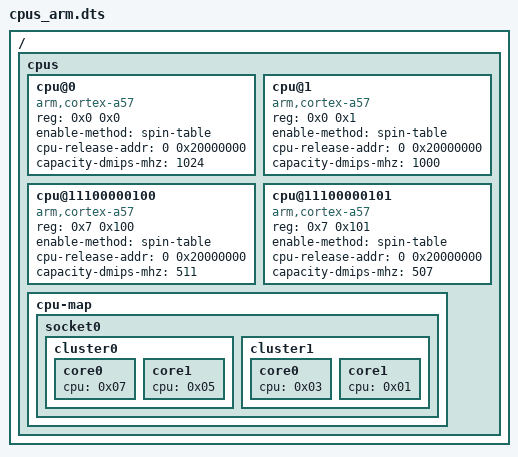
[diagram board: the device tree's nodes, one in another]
// Copyright 2023 The Fuchsia Authors. All rights reserved.
// Use of this source code is governed by a BSD-style license that can be
// found in the LICENSE file.

/dts-v1/;

/ {
    cpus {
        #size-cells = <0>;
        #address-cells = <2>;

        cpu@0 {
            device_type = "cpu";
            compatible = "arm,cortex-a57";
            reg = <0x0 0x0>;
            enable-method = "spin-table";
            cpu-release-addr = <0 0x20000000>;
            phandle = <0x01>;
            capacity-dmips-mhz = <1024>;
        };

        cpu@1 {
            device_type = "cpu";
            compatible = "arm,cortex-a57";
            reg = <0x0 0x1>;
            enable-method = "spin-table";
            cpu-release-addr = <0 0x20000000>;
            phandle = <0x03>;
            capacity-dmips-mhz = <1000>;
        };

        cpu@11100000100 {
            device_type = "cpu";
            compatible = "arm,cortex-a57";
            reg = <0x7 0x100>;
            enable-method = "spin-table";
            cpu-release-addr = <0 0x20000000>;
            phandle = <0x05>;
            capacity-dmips-mhz = <511>;
        };

        cpu@11100000101 {
            device_type = "cpu";
            compatible = "arm,cortex-a57";
            reg = <0x7 0x101>;
            enable-method = "spin-table";
            cpu-release-addr = <0 0x20000000>;
            phandle = <0x07>;
            capacity-dmips-mhz = <507>;
        };

        cpu-map {
            socket0 {
                cluster0 {
                    core0 {
                        cpu = <0x07>;
                    };

                    core1 {
                        cpu = <0x05>;
                    };
                };
                cluster1 {
                    core0 {
                        cpu = <0x03>;
                    };

                    core1 {
                        cpu = <0x01>;
                    };
                };
            };
        };
    };
};
